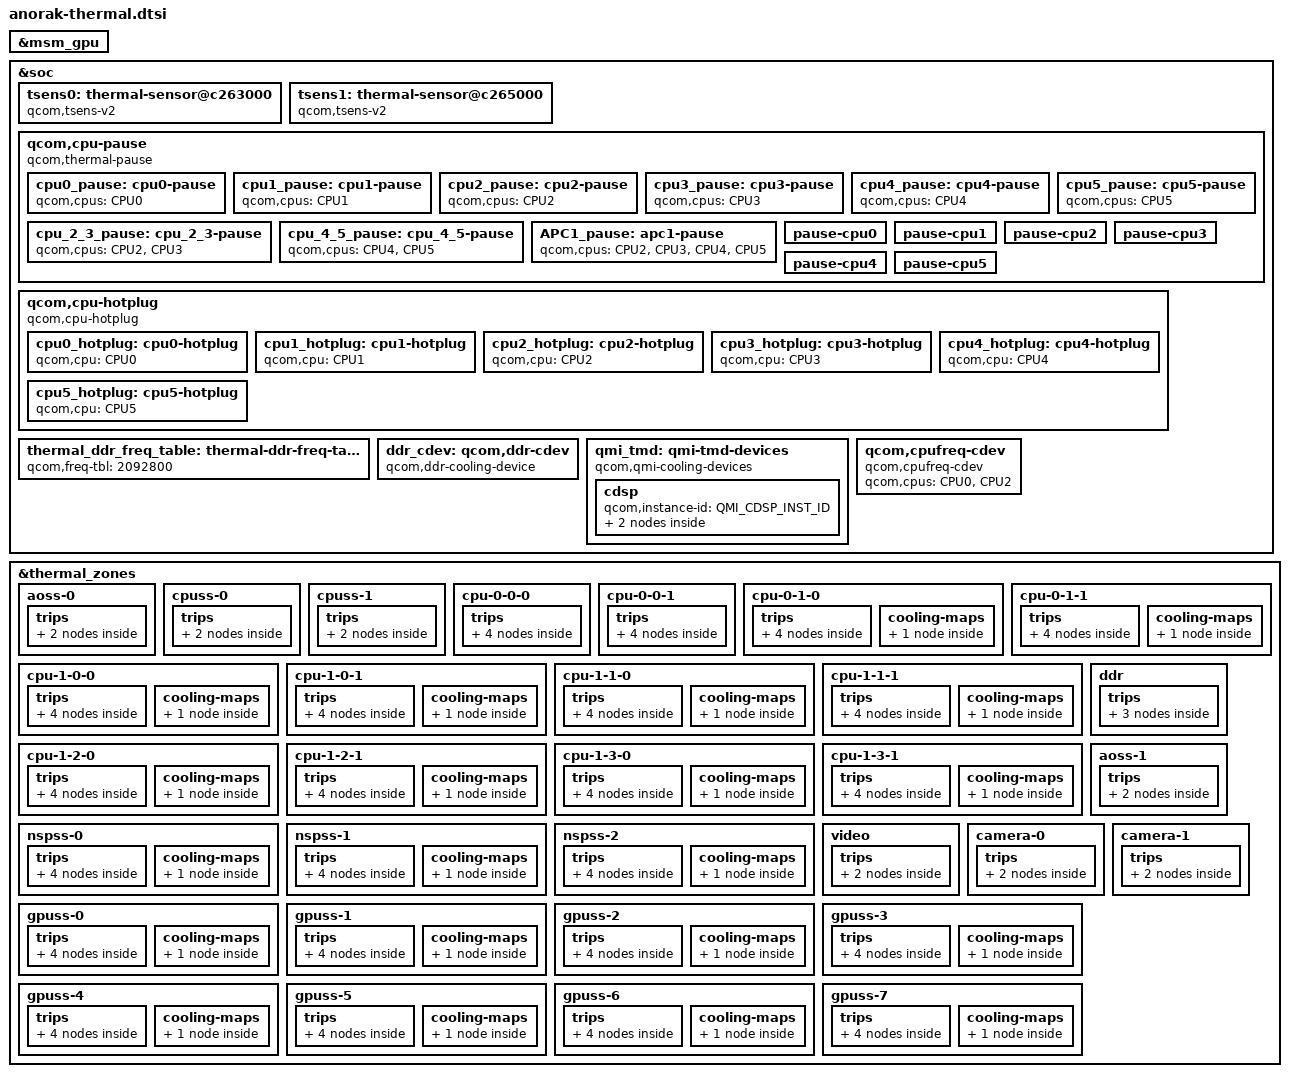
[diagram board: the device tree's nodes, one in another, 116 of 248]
#include <dt-bindings/thermal/thermal_qti.h>

&msm_gpu {
	#cooling-cells = <2>;
};

&soc {
	tsens0: thermal-sensor@c263000 {
		compatible = "qcom,tsens-v2";
		reg = <0x0c263000 0x1ff>, /* TM */
			<0x0c222000 0x1ff>; /* SROT */
		#qcom,sensors = <16>;
		interrupts = <GIC_SPI 506 IRQ_TYPE_LEVEL_HIGH>,
			     <GIC_SPI 508 IRQ_TYPE_LEVEL_HIGH>;
		interrupt-names = "uplow","critical";
		#thermal-sensor-cells = <1>;
	};

	tsens1: thermal-sensor@c265000 {
		compatible = "qcom,tsens-v2";
		reg = <0x0c265000 0x1ff>, /* TM */
			<0x0c223000 0x1ff>; /* SROT */
		#qcom,sensors = <16>;
		interrupts = <GIC_SPI 507 IRQ_TYPE_LEVEL_HIGH>,
			     <GIC_SPI 509 IRQ_TYPE_LEVEL_HIGH>;
		interrupt-names = "uplow","critical";
		#thermal-sensor-cells = <1>;
	};

	qcom,cpu-pause {
		compatible = "qcom,thermal-pause";

		cpu0_pause: cpu0-pause {
			qcom,cpus = <&CPU0>;
			#cooling-cells = <2>;
		};

		cpu1_pause: cpu1-pause {
			qcom,cpus = <&CPU1>;
			#cooling-cells = <2>;
		};

		cpu2_pause: cpu2-pause {
			qcom,cpus = <&CPU2>;
			#cooling-cells = <2>;
		};

		cpu3_pause: cpu3-pause {
			qcom,cpus = <&CPU3>;
			#cooling-cells = <2>;
		};

		cpu4_pause: cpu4-pause {
			qcom,cpus = <&CPU4>;
			#cooling-cells = <2>;
		};

		cpu5_pause: cpu5-pause {
			qcom,cpus = <&CPU5>;
			#cooling-cells = <2>;
		};

		cpu_2_3_pause: cpu_2_3-pause {
			qcom,cpus = <&CPU2 &CPU3>;
			#cooling-cells = <2>;
		};

		cpu_4_5_pause: cpu_4_5-pause {
			qcom,cpus = <&CPU4 &CPU5>;
			#cooling-cells = <2>;
		};

		APC1_pause: apc1-pause {
			qcom,cpus = <&CPU2 &CPU3 &CPU4 &CPU5>;
			#cooling-cells = <2>;
		};

		/* Thermal-engine cooling devices */
		pause-cpu0 {
			qcom,cpus = <&CPU0>;
			qcom,cdev-alias = "pause-cpu0";
		};

		pause-cpu1 {
			qcom,cpus = <&CPU1>;
			qcom,cdev-alias = "pause-cpu1";
		};

		pause-cpu2 {
			qcom,cpus = <&CPU2>;
			qcom,cdev-alias = "pause-cpu2";
		};

		pause-cpu3 {
			qcom,cpus = <&CPU3>;
			qcom,cdev-alias = "pause-cpu3";
		};

		pause-cpu4 {
			qcom,cpus = <&CPU4>;
			qcom,cdev-alias = "pause-cpu4";
		};

		pause-cpu5 {
			qcom,cpus = <&CPU5>;
			qcom,cdev-alias = "pause-cpu5";
		};
	};

	qcom,cpu-hotplug {
		compatible = "qcom,cpu-hotplug";

		cpu0_hotplug: cpu0-hotplug {
			qcom,cpu = <&CPU0>;
			#cooling-cells = <2>;
		};

		cpu1_hotplug: cpu1-hotplug {
			qcom,cpu = <&CPU1>;
			#cooling-cells = <2>;
		};

		cpu2_hotplug: cpu2-hotplug {
			qcom,cpu = <&CPU2>;
			#cooling-cells = <2>;
		};

		cpu3_hotplug: cpu3-hotplug {
			qcom,cpu = <&CPU3>;
			#cooling-cells = <2>;
		};

		cpu4_hotplug: cpu4-hotplug {
			qcom,cpu = <&CPU4>;
			#cooling-cells = <2>;
		};

		cpu5_hotplug: cpu5-hotplug {
			qcom,cpu = <&CPU5>;
			#cooling-cells = <2>;
		};
	};

	thermal_ddr_freq_table: thermal-ddr-freq-table {
		qcom,freq-tbl = < 2092800 >;
	};

	ddr_cdev: qcom,ddr-cdev {
		compatible = "qcom,ddr-cooling-device";
		#cooling-cells = <2>;
		qcom,freq-table = <&thermal_ddr_freq_table>;
		qcom,bus-width = <4>;
		interconnects = <&mc_virt MASTER_LLCC &mc_virt SLAVE_EBI1>;
	};

	qmi_tmd: qmi-tmd-devices {
		compatible = "qcom,qmi-cooling-devices";
		cdsp {
			qcom,instance-id = <QMI_CDSP_INST_ID>;

			cdsp_sw: cdsp {
				qcom,qmi-dev-name = "cdsp_sw";
				#cooling-cells = <2>;
			};

			cdsp_hw: cdsp_hw {
				qcom,qmi-dev-name = "cdsp_hw";
				#cooling-cells = <2>;
			};
		};
	};

	qcom,cpufreq-cdev {
		compatible = "qcom,cpufreq-cdev";
		qcom,cpus = <&CPU0 &CPU2>;
	};
};

&thermal_zones {
	aoss-0 {
		polling-delay-passive = <0>;
		polling-delay = <0>;
		thermal-sensors = <&tsens0 0>;
		trips {
			thermal-engine-config {
				temperature = <125000>;
				hysteresis = <1000>;
				type = "passive";
			};

			reset-mon-cfg {
				temperature = <115000>;
				hysteresis = <5000>;
				type = "passive";
			};
		};
	};

	cpuss-0 {
		polling-delay-passive = <0>;
		polling-delay = <0>;
		thermal-sensors = <&tsens0 1>;
		trips {
			thermal-engine-config {
				temperature = <125000>;
				hysteresis = <1000>;
				type = "passive";
			};

			reset-mon-cfg {
				temperature = <115000>;
				hysteresis = <5000>;
				type = "passive";
			};
		};
	};

	cpuss-1 {
		polling-delay-passive = <0>;
		polling-delay = <0>;
		thermal-sensors = <&tsens0 2>;
		trips {
			thermal-engine-config {
				temperature = <125000>;
				hysteresis = <1000>;
				type = "passive";
			};

			reset-mon-cfg {
				temperature = <115000>;
				hysteresis = <5000>;
				type = "passive";
			};
		};
	};

	cpu-0-0-0 {
		polling-delay-passive = <0>;
		polling-delay = <0>;
		thermal-sensors = <&tsens0 3>;
		trips {
			thermal-engine-config {
				temperature = <125000>;
				hysteresis = <1000>;
				type = "passive";
			};

			thermal-hal-config {
				temperature = <125000>;
				hysteresis = <1000>;
				type = "passive";
			};

			reset-mon-cfg {
				temperature = <115000>;
				hysteresis = <5000>;
				type = "passive";
			};

			cpu0_emerg0: cpu0-emerg0-cfg {
				temperature = <110000>;
				hysteresis = <10000>;
				type = "passive";
			};
		};
	};

	cpu-0-0-1 {
		polling-delay-passive = <0>;
		polling-delay = <0>;
		thermal-sensors = <&tsens0 4>;
		trips {
			thermal-engine-config {
				temperature = <125000>;
				hysteresis = <1000>;
				type = "passive";
			};

			thermal-hal-config {
				temperature = <125000>;
				hysteresis = <1000>;
				type = "passive";
			};

			reset-mon-cfg {
				temperature = <115000>;
				hysteresis = <5000>;
				type = "passive";
			};

			cpu0_emerg1: cpu0-emerg1-cfg {
				temperature = <110000>;
				hysteresis = <10000>;
				type = "passive";
			};
		};
	};

	cpu-0-1-0 {
		polling-delay-passive = <0>;
		polling-delay = <0>;
		thermal-sensors = <&tsens0 5>;
		trips {
			thermal-engine-config {
				temperature = <125000>;
				hysteresis = <1000>;
				type = "passive";
			};

			thermal-hal-config {
				temperature = <125000>;
				hysteresis = <1000>;
				type = "passive";
			};

			reset-mon-cfg {
				temperature = <115000>;
				hysteresis = <5000>;
				type = "passive";
			};

			cpu1_emerg0: cpu1-emerg0-cfg {
				temperature = <110000>;
				hysteresis = <10000>;
				type = "passive";
			};
		};

		cooling-maps {
			cpu010_cdev {
				trip = <&cpu1_emerg0>;
				cooling-device = <&cpu1_pause 1 1>;
			};
		};
	};

	cpu-0-1-1 {
		polling-delay-passive = <0>;
		polling-delay = <0>;
		thermal-sensors = <&tsens0 6>;
		trips {
			thermal-engine-config {
				temperature = <125000>;
				hysteresis = <1000>;
				type = "passive";
			};

			thermal-hal-config {
				temperature = <125000>;
				hysteresis = <1000>;
				type = "passive";
			};

			reset-mon-cfg {
				temperature = <115000>;
				hysteresis = <5000>;
				type = "passive";
			};

			cpu1_emerg1: cpu1-emerg1-cfg {
				temperature = <110000>;
				hysteresis = <10000>;
				type = "passive";
			};
		};

		cooling-maps {
			cpu011_cdev {
				trip = <&cpu1_emerg1>;
				cooling-device = <&cpu1_pause 1 1>;
			};
		};
	};

	cpu-1-0-0 {
		polling-delay-passive = <0>;
		polling-delay = <0>;
		thermal-sensors = <&tsens0 7>;
		trips {
			thermal-engine-config {
				temperature = <125000>;
				hysteresis = <1000>;
				type = "passive";
			};

			thermal-hal-config {
				temperature = <125000>;
				hysteresis = <1000>;
				type = "passive";
			};

			reset-mon-cfg {
				temperature = <115000>;
				hysteresis = <5000>;
				type = "passive";
			};

			cpu2_emerg0: cpu2-emerg0-cfg {
				temperature = <110000>;
				hysteresis = <10000>;
				type = "passive";
			};
		};

		cooling-maps {
			cpu100_cdev {
				trip = <&cpu2_emerg0>;
				cooling-device = <&cpu2_pause 1 1>;
			};
		};
	};

	cpu-1-0-1 {
		polling-delay-passive = <0>;
		polling-delay = <0>;
		thermal-sensors = <&tsens0 8>;
		trips {
			thermal-engine-config {
				temperature = <125000>;
				hysteresis = <1000>;
				type = "passive";
			};

			thermal-hal-config {
				temperature = <125000>;
				hysteresis = <1000>;
				type = "passive";
			};

			reset-mon-cfg {
				temperature = <115000>;
				hysteresis = <5000>;
				type = "passive";
			};

			cpu2_emerg1: cpu2-emerg1-cfg {
				temperature = <110000>;
				hysteresis = <10000>;
				type = "passive";
			};
		};

		cooling-maps {
			cpu101_cdev {
				trip = <&cpu2_emerg1>;
				cooling-device = <&cpu2_pause 1 1>;
			};
		};
	};

	cpu-1-1-0 {
		polling-delay-passive = <0>;
		polling-delay = <0>;
		thermal-sensors = <&tsens0 9>;
		trips {
			thermal-engine-config {
				temperature = <125000>;
				hysteresis = <1000>;
				type = "passive";
			};

			thermal-hal-config {
				temperature = <125000>;
				hysteresis = <1000>;
				type = "passive";
			};

			reset-mon-cfg {
				temperature = <115000>;
				hysteresis = <5000>;
				type = "passive";
			};

			cpu3_emerg0: cpu3-emerg0-cfg {
				temperature = <110000>;
				hysteresis = <10000>;
				type = "passive";
			};
		};

		cooling-maps {
			cpu110_cdev {
				trip = <&cpu3_emerg0>;
				cooling-device = <&cpu3_pause 1 1>;
			};
		};
	};

	cpu-1-1-1 {
		polling-delay-passive = <0>;
		polling-delay = <0>;
		thermal-sensors = <&tsens0 10>;
		trips {
			thermal-engine-config {
				temperature = <125000>;
				hysteresis = <1000>;
				type = "passive";
			};

			thermal-hal-config {
				temperature = <125000>;
				hysteresis = <1000>;
				type = "passive";
			};

			reset-mon-cfg {
				temperature = <115000>;
				hysteresis = <5000>;
				type = "passive";
			};

			cpu3_emerg1: cpu3-emerg1-cfg {
				temperature = <110000>;
				hysteresis = <10000>;
				type = "passive";
			};
		};

		cooling-maps {
			cpu111_cdev {
				trip = <&cpu3_emerg1>;
				cooling-device = <&cpu3_pause 1 1>;
			};
		};
	};

	cpu-1-2-0 {
		polling-delay-passive = <0>;
		polling-delay = <0>;
		thermal-sensors = <&tsens0 11>;
		trips {
			thermal-engine-config {
				temperature = <125000>;
				hysteresis = <1000>;
				type = "passive";
			};

			thermal-hal-config {
				temperature = <125000>;
				hysteresis = <1000>;
				type = "passive";
			};

			reset-mon-cfg {
				temperature = <115000>;
				hysteresis = <5000>;
				type = "passive";
			};

			cpu4_emerg0: cpu4-emerg0-cfg {
				temperature = <110000>;
				hysteresis = <10000>;
				type = "passive";
			};
		};

		cooling-maps {
			cpu120_cdev {
				trip = <&cpu4_emerg0>;
				cooling-device = <&cpu4_pause 1 1>;
			};
		};
	};

	cpu-1-2-1 {
		polling-delay-passive = <0>;
		polling-delay = <0>;
		thermal-sensors = <&tsens0 12>;
		trips {
			thermal-engine-config {
				temperature = <125000>;
				hysteresis = <1000>;
				type = "passive";
			};

			thermal-hal-config {
				temperature = <125000>;
				hysteresis = <1000>;
				type = "passive";
			};

			reset-mon-cfg {
				temperature = <115000>;
				hysteresis = <5000>;
				type = "passive";
			};

			cpu4_emerg1: cpu4-emerg1-cfg {
				temperature = <110000>;
				hysteresis = <10000>;
				type = "passive";
			};
		};

		cooling-maps {
			cpu121_cdev {
				trip = <&cpu4_emerg1>;
				cooling-device = <&cpu4_pause 1 1>;
			};
		};
	};

	cpu-1-3-0 {
		polling-delay-passive = <0>;
		polling-delay = <0>;
		thermal-sensors = <&tsens0 13>;
		trips {
			thermal-engine-config {
				temperature = <125000>;
				hysteresis = <1000>;
				type = "passive";
			};

			thermal-hal-config {
				temperature = <125000>;
				hysteresis = <1000>;
				type = "passive";
			};

			reset-mon-cfg {
				temperature = <115000>;
				hysteresis = <5000>;
				type = "passive";
			};

			cpu5_emerg0: cpu5-emerg0-cfg {
				temperature = <110000>;
				hysteresis = <10000>;
				type = "passive";
			};
		};

		cooling-maps {
			cpu130_cdev {
				trip = <&cpu5_emerg0>;
				cooling-device = <&cpu5_pause 1 1>;
			};
		};
	};

	cpu-1-3-1 {
		polling-delay-passive = <0>;
		polling-delay = <0>;
		thermal-sensors = <&tsens0 14>;
		trips {
			thermal-engine-config {
				temperature = <125000>;
				hysteresis = <1000>;
				type = "passive";
			};

			thermal-hal-config {
				temperature = <125000>;
				hysteresis = <1000>;
				type = "passive";
			};

			reset-mon-cfg {
				temperature = <115000>;
				hysteresis = <5000>;
				type = "passive";
			};

			cpu5_emerg1: cpu5-emerg1-cfg {
				temperature = <110000>;
				hysteresis = <10000>;
				type = "passive";
			};
		};

		cooling-maps {
			cpu131_cdev {
				trip = <&cpu5_emerg1>;
				cooling-device = <&cpu5_pause 1 1>;
			};
		};
	};

	ddr {
		polling-delay-passive = <10>;
		polling-delay = <0>;
		thermal-sensors = <&tsens0 15>;
		trips {
			thermal-engine-config {
				temperature = <125000>;
				hysteresis = <1000>;
				type = "passive";
			};

			ddr_config0: ddr0-config {
				temperature = <90000>;
				hysteresis = <5000>;
				type = "passive";
			};

			reset-mon-cfg {
				temperature = <115000>;
				hysteresis = <5000>;
				type = "passive";
			};
		};
	};

	aoss-1 {
		polling-delay-passive = <0>;
		polling-delay = <0>;
		thermal-sensors = <&tsens1 0>;
		trips {
			thermal-engine-config {
				temperature = <125000>;
				hysteresis = <1000>;
				type = "passive";
			};

			reset-mon-cfg {
				temperature = <115000>;
				hysteresis = <5000>;
				type = "passive";
			};
		};
	};

	nspss-0 {
		polling-delay-passive = <10>;
		polling-delay = <0>;
		thermal-sensors = <&tsens1 1>;
		trips {
			thermal-engine-config {
				temperature = <125000>;
				hysteresis = <1000>;
				type = "passive";
			};

			thermal-hal-config {
				temperature = <125000>;
				hysteresis = <1000>;
				type = "passive";
			};

			reset-mon-cfg {
				temperature = <115000>;
				hysteresis = <5000>;
				type = "passive";
			};

			nspss_0_config: junction-config {
				temperature = <95000>;
				hysteresis = <5000>;
				type = "passive";
			};
		};

		cooling-maps {
			nsp_cdev {
				trip = <&nspss_0_config>;
				cooling-device = <&cdsp_sw THERMAL_NO_LIMIT
							THERMAL_NO_LIMIT>;
			};
		};
	};

	nspss-1 {
		polling-delay-passive = <10>;
		polling-delay = <0>;
		thermal-sensors = <&tsens1 2>;
		trips {
			thermal-engine-config {
				temperature = <125000>;
				hysteresis = <1000>;
				type = "passive";
			};

			thermal-hal-config {
				temperature = <125000>;
				hysteresis = <1000>;
				type = "passive";
			};

			reset-mon-cfg {
				temperature = <115000>;
				hysteresis = <5000>;
				type = "passive";
			};

			nspss_1_config: junction-config {
				temperature = <95000>;
				hysteresis = <5000>;
				type = "passive";
			};
		};

		cooling-maps {
			nsp_cdev {
				trip = <&nspss_1_config>;
				cooling-device = <&cdsp_sw THERMAL_NO_LIMIT
							THERMAL_NO_LIMIT>;
			};
		};
	};

	nspss-2 {
		polling-delay-passive = <10>;
		polling-delay = <0>;
		thermal-sensors = <&tsens1 3>;
		trips {
			thermal-engine-config {
				temperature = <125000>;
				hysteresis = <1000>;
				type = "passive";
			};

			thermal-hal-config {
				temperature = <125000>;
				hysteresis = <1000>;
				type = "passive";
			};

			reset-mon-cfg {
				temperature = <115000>;
				hysteresis = <5000>;
				type = "passive";
			};

			nspss_2_config: junction-config {
				temperature = <95000>;
				hysteresis = <5000>;
				type = "passive";
			};
		};

		cooling-maps {
			nsp_cdev {
				trip = <&nspss_2_config>;
				cooling-device = <&cdsp_sw THERMAL_NO_LIMIT
							THERMAL_NO_LIMIT>;
			};
		};
	};


	video {
		polling-delay-passive = <10>;
		polling-delay = <0>;
		thermal-sensors = <&tsens1 4>;
		trips {
			thermal-engine-config {
				temperature = <125000>;
				hysteresis = <1000>;
				type = "passive";
			};

			reset-mon-cfg {
				temperature = <115000>;
				hysteresis = <5000>;
				type = "passive";
			};
		};
	};

	camera-0 {
		polling-delay-passive = <10>;
		polling-delay = <0>;
		thermal-sensors = <&tsens1 5>;
		trips {
			thermal-engine-config {
				temperature = <125000>;
				hysteresis = <1000>;
				type = "passive";
			};

			reset-mon-cfg {
				temperature = <115000>;
				hysteresis = <5000>;
				type = "passive";
			};
		};
	};

	camera-1 {
		polling-delay-passive = <10>;
		polling-delay = <0>;
		thermal-sensors = <&tsens1 6>;
		trips {
			thermal-engine-config {
				temperature = <125000>;
				hysteresis = <1000>;
				type = "passive";
			};

			reset-mon-cfg {
				temperature = <115000>;
				hysteresis = <5000>;
				type = "passive";
			};
		};
	};

	gpuss-0 {
		polling-delay-passive = <10>;
		polling-delay = <0>;
		thermal-sensors = <&tsens1 7>;
		trips {
			thermal-engine-config {
				temperature = <125000>;
				hysteresis = <1000>;
				type = "passive";
			};

			thermal-hal-config {
				temperature = <125000>;
				hysteresis = <1000>;
				type = "passive";
			};

			reset-mon-cfg {
				temperature = <115000>;
				hysteresis = <5000>;
				type = "passive";
			};

			gpu0_tj_cfg: tj_cfg {
				temperature = <95000>;
				hysteresis = <5000>;
				type = "passive";
			};
		};

		cooling-maps {
			gpu0_cdev {
				trip = <&gpu0_tj_cfg>;
				cooling-device = <&msm_gpu 0 THERMAL_NO_LIMIT>;
			};
		};
	};

	gpuss-1 {
		polling-delay-passive = <10>;
		polling-delay = <0>;
		thermal-sensors = <&tsens1 8>;
		trips {
			thermal-engine-config {
				temperature = <125000>;
				hysteresis = <1000>;
				type = "passive";
			};

			thermal-hal-config {
				temperature = <125000>;
				hysteresis = <1000>;
				type = "passive";
			};

			reset-mon-cfg {
				temperature = <115000>;
				hysteresis = <5000>;
				type = "passive";
			};

			gpu1_tj_cfg: tj_cfg {
				temperature = <95000>;
				hysteresis = <5000>;
				type = "passive";
			};
		};

		cooling-maps {
			gpu1_cdev {
				trip = <&gpu1_tj_cfg>;
				cooling-device = <&msm_gpu 0 THERMAL_NO_LIMIT>;
			};
		};
	};

	gpuss-2 {
		polling-delay-passive = <10>;
		polling-delay = <0>;
		thermal-sensors = <&tsens1 9>;
		trips {
			thermal-engine-config {
				temperature = <125000>;
				hysteresis = <1000>;
				type = "passive";
			};

			thermal-hal-config {
				temperature = <125000>;
				hysteresis = <1000>;
				type = "passive";
			};

			reset-mon-cfg {
				temperature = <115000>;
				hysteresis = <5000>;
				type = "passive";
			};

			gpu2_tj_cfg: tj_cfg {
				temperature = <95000>;
				hysteresis = <5000>;
				type = "passive";
			};
		};

		cooling-maps {
			gpu2_cdev {
				trip = <&gpu2_tj_cfg>;
				cooling-device = <&msm_gpu 0 THERMAL_NO_LIMIT>;
			};
		};
	};

	gpuss-3 {
		polling-delay-passive = <10>;
		polling-delay = <0>;
		thermal-sensors = <&tsens1 10>;
		trips {
			thermal-engine-config {
				temperature = <125000>;
				hysteresis = <1000>;
				type = "passive";
			};

			thermal-hal-config {
				temperature = <125000>;
				hysteresis = <1000>;
				type = "passive";
			};

			reset-mon-cfg {
				temperature = <115000>;
				hysteresis = <5000>;
				type = "passive";
			};

			gpu3_tj_cfg: tj_cfg {
				temperature = <95000>;
				hysteresis = <5000>;
				type = "passive";
			};
		};

		cooling-maps {
			gpu3_cdev {
				trip = <&gpu3_tj_cfg>;
				cooling-device = <&msm_gpu 0 THERMAL_NO_LIMIT>;
			};
		};
	};

	gpuss-4 {
		polling-delay-passive = <10>;
		polling-delay = <0>;
		thermal-sensors = <&tsens1 11>;
		trips {
			thermal-engine-config {
				temperature = <125000>;
				hysteresis = <1000>;
				type = "passive";
			};

			thermal-hal-config {
				temperature = <125000>;
				hysteresis = <1000>;
				type = "passive";
			};

			reset-mon-cfg {
				temperature = <115000>;
				hysteresis = <5000>;
				type = "passive";
			};

			gpu4_tj_cfg: tj_cfg {
				temperature = <95000>;
				hysteresis = <5000>;
				type = "passive";
			};
		};

		cooling-maps {
			gpu4_cdev {
				trip = <&gpu4_tj_cfg>;
				cooling-device = <&msm_gpu 0 THERMAL_NO_LIMIT>;
			};
		};
	};

	gpuss-5 {
		polling-delay-passive = <10>;
		polling-delay = <0>;
		thermal-sensors = <&tsens1 12>;
		trips {
			thermal-engine-config {
				temperature = <125000>;
				hysteresis = <1000>;
				type = "passive";
			};

			thermal-hal-config {
				temperature = <125000>;
				hysteresis = <1000>;
				type = "passive";
			};

			reset-mon-cfg {
				temperature = <115000>;
				hysteresis = <5000>;
				type = "passive";
			};

			gpu5_tj_cfg: tj_cfg {
				temperature = <95000>;
				hysteresis = <5000>;
				type = "passive";
			};
		};

		cooling-maps {
			gpu5_cdev {
				trip = <&gpu5_tj_cfg>;
				cooling-device = <&msm_gpu 0 THERMAL_NO_LIMIT>;
			};
		};
	};

	gpuss-6 {
		polling-delay-passive = <10>;
		polling-delay = <0>;
		thermal-sensors = <&tsens1 13>;
		trips {
			thermal-engine-config {
				temperature = <125000>;
				hysteresis = <1000>;
				type = "passive";
			};

			thermal-hal-config {
				temperature = <125000>;
				hysteresis = <1000>;
				type = "passive";
			};

			reset-mon-cfg {
				temperature = <115000>;
				hysteresis = <5000>;
				type = "passive";
			};

			gpu6_tj_cfg: tj_cfg {
				temperature = <95000>;
				hysteresis = <5000>;
				type = "passive";
			};
		};

		cooling-maps {
			gpu6_cdev {
				trip = <&gpu6_tj_cfg>;
				cooling-device = <&msm_gpu 0 THERMAL_NO_LIMIT>;
			};
		};
	};

	gpuss-7 {
		polling-delay-passive = <10>;
		polling-delay = <0>;
		thermal-sensors = <&tsens1 14>;
		trips {
			thermal-engine-config {
				temperature = <125000>;
				hysteresis = <1000>;
				type = "passive";
			};

			thermal-hal-config {
				temperature = <125000>;
				hysteresis = <1000>;
				type = "passive";
			};

			reset-mon-cfg {
				temperature = <115000>;
				hysteresis = <5000>;
				type = "passive";
			};

			gpu7_tj_cfg: tj_cfg {
				temperature = <95000>;
				hysteresis = <5000>;
				type = "passive";
			};
		};

		cooling-maps {
			gpu7_cdev {
				trip = <&gpu7_tj_cfg>;
				cooling-device = <&msm_gpu 0 THERMAL_NO_LIMIT>;
			};
		};
	};
};
